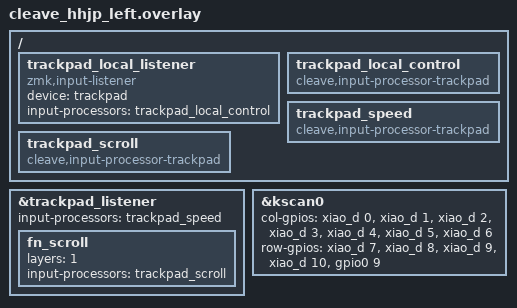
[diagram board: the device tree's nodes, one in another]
/*
 * Copyright (c) 2025
 * SPDX-License-Identifier: MIT
 */

#include "cleave_hhjp.dtsi"
#include "cleave_hhjp_trackpad.dtsi"
#include "cleave_hhjp_trackpad_spi.dtsi"
#include <input/processors.dtsi>

&trackpad_listener {
	status = "okay";
	input-processors = <&trackpad_speed>;

	/* Fn (LANG2 hold or either dedicated Fn): vertical scrolling only.
	 * Suppress X drift, scale Y with fractional remainders, then map to wheel.
	 * Pointer-up is negative Y; wheel-up is positive. */
	fn_scroll {
		layers = <1>;
		input-processors = <&trackpad_scroll>;
	};
};

/ {
	trackpad_local_listener: trackpad_local_listener {
		compatible = "zmk,input-listener";
		device = <&trackpad>;
		input-processors = <&trackpad_local_control>;
	};
	trackpad_local_control: trackpad_local_control {
		compatible = "cleave,input-processor-trackpad";
		#input-processor-cells = <0>;
	};
	trackpad_speed: trackpad_speed {
		compatible = "cleave,input-processor-trackpad";
		#input-processor-cells = <0>;
	};
	trackpad_scroll: trackpad_scroll {
		compatible = "cleave,input-processor-trackpad";
		#input-processor-cells = <0>;
	};
};

&kscan0 {
	col-gpios
		= <&xiao_d 0 GPIO_ACTIVE_HIGH>
		, <&xiao_d 1 GPIO_ACTIVE_HIGH>
		, <&xiao_d 2 GPIO_ACTIVE_HIGH>
		, <&xiao_d 3 GPIO_ACTIVE_HIGH>
		, <&xiao_d 4 GPIO_ACTIVE_HIGH>
		, <&xiao_d 5 GPIO_ACTIVE_HIGH>
		, <&xiao_d 6 GPIO_ACTIVE_HIGH>
		;

	row-gpios
		= <&xiao_d 7 (GPIO_ACTIVE_HIGH | GPIO_PULL_DOWN)>
		, <&xiao_d 8 (GPIO_ACTIVE_HIGH | GPIO_PULL_DOWN)>
		, <&xiao_d 9 (GPIO_ACTIVE_HIGH | GPIO_PULL_DOWN)>
		, <&xiao_d 10 (GPIO_ACTIVE_HIGH | GPIO_PULL_DOWN)>
		, <&gpio0 9 (GPIO_ACTIVE_HIGH | GPIO_PULL_DOWN)>   // NFC1 (P0.09)
		;
};
